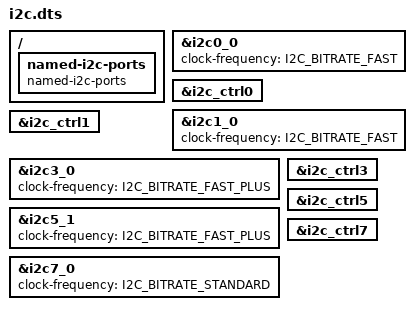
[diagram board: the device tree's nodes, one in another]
/* Copyright 2021 The Chromium OS Authors. All rights reserved.
 * Use of this source code is governed by a BSD-style license that can be
 * found in the LICENSE file.
 */

/ {
	named-i2c-ports {
		compatible = "named-i2c-ports";
	};
};

&i2c0_0 {
	status = "okay";
	clock-frequency = <I2C_BITRATE_FAST>;
};

&i2c_ctrl0 {
	status = "okay";
};

&i2c1_0 {
	status = "okay";
	clock-frequency = <I2C_BITRATE_FAST>;
};

&i2c_ctrl1 {
	status = "okay";
};

&i2c3_0 {
	status = "okay";
	clock-frequency = <I2C_BITRATE_FAST_PLUS>;
};

&i2c_ctrl3 {
	status = "okay";
};

&i2c5_1 {
	status = "okay";
	clock-frequency = <I2C_BITRATE_FAST_PLUS>;
};

&i2c_ctrl5 {
	status = "okay";
};

&i2c7_0 {
	status = "okay";
	clock-frequency = <I2C_BITRATE_STANDARD>;
};

&i2c_ctrl7 {
	status = "okay";
};
